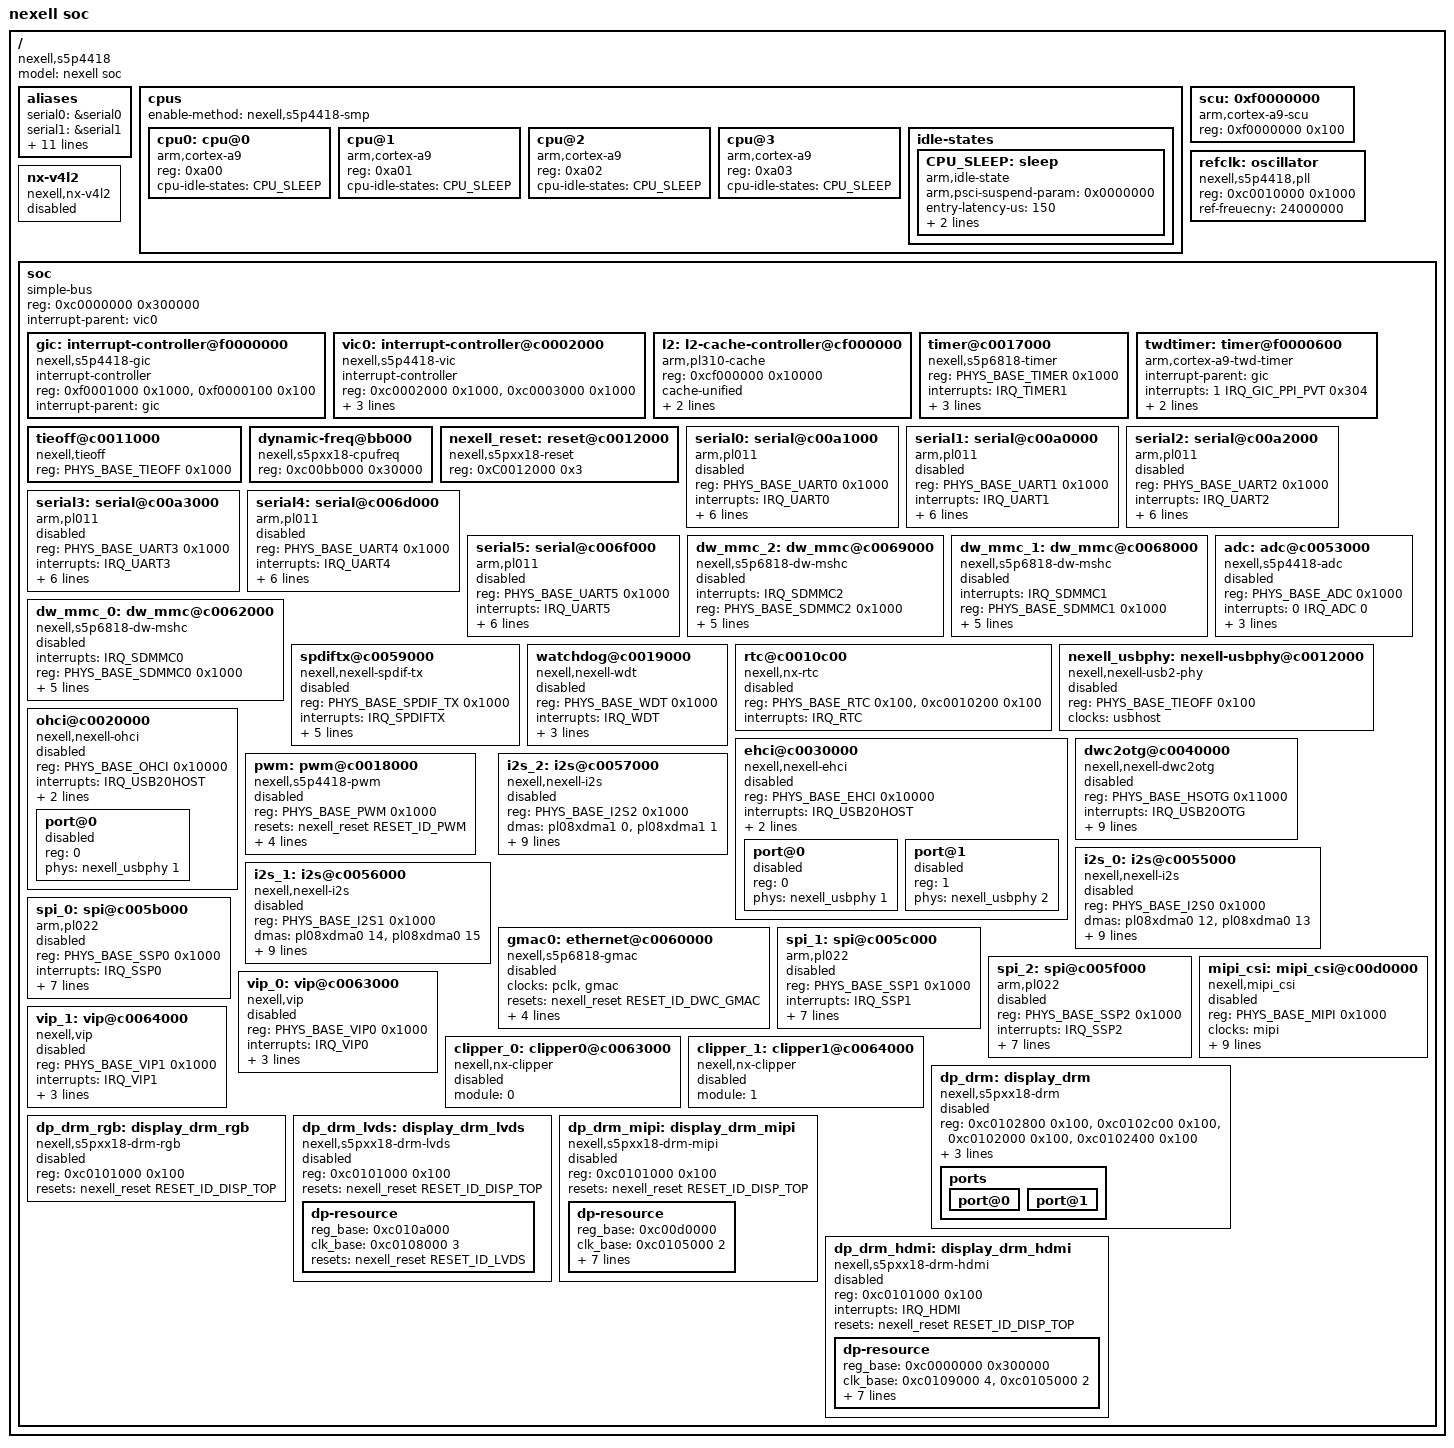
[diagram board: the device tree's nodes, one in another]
/*
 * Copyright (C) 2016  Nexell Co., Ltd.
 * Author: Youngbok, Park <ybpark@nexell.co.kr>
 *
 * This program is free software; you can redistribute it and/or
 * modify it under the terms of the GNU General Public License
 * as published by the Free Software Foundation; either version 2
 * of the License, or (at your option) any later version.
 *
 * This program is distributed in the hope that it will be useful,
 * but WITHOUT ANY WARRANTY; without even the implied warranty of
 * MERCHANTABILITY or FITNESS FOR A PARTICULAR PURPOSE.  See the
 * GNU General Public License for more details.
 *
 * You should have received a copy of the GNU General Public License
 * along with this program.  If not, see <http://www.gnu.org/licenses/>.
 */

#include "../skeleton.dtsi"

#include <dt-bindings/tieoff/s5p4418-tieoff.h>
#include <dt-bindings/soc/s5p4418-base.h>
#include <dt-bindings/reset/nexell,s5p4418-reset.h>
#include <dt-bindings/interrupt-controller/s5p4418-irq.h>
#include <dt-bindings/media/nexell-vip.h>

/ {
	model = "nexell soc";
	compatible = "nexell,s5p4418";
	#address-cells = <0x1>;
	#size-cells = <0x1>;

	aliases {
		serial0 = &serial0;
		serial1 = &serial1;
		serial2 = &serial2;
		serial3 = &serial3;
		serial4 = &serial4;
		serial5 = &serial5;
		i2s0	= &i2s_0;
		i2s1	= &i2s_1;
		i2s2	= &i2s_2;
		spi0	= &spi_0;
		spi1	= &spi_1;
		spi2	= &spi_2;
		pinctrl0 = &pinctrl_0;
	};

	cpus {
		#address-cells = <0x1>;
		#size-cells = <0x0>;
		enable-method = "nexell,s5p4418-smp";

		cpu0: cpu@0 {
			device_type = "cpu";
			compatible = "arm,cortex-a9";
			#cooling-cells = <2>;
			reg = <0xa00>;
			cpu-idle-states =<&CPU_SLEEP>;

		};

		cpu@1 {
			device_type = "cpu";
			compatible = "arm,cortex-a9";
			reg = <0xa01>;
			cpu-idle-states =<&CPU_SLEEP>;
		};

		cpu@2 {
			device_type = "cpu";
			compatible = "arm,cortex-a9";
			reg = <0xa02>;
			cpu-idle-states =<&CPU_SLEEP>;
		};

		cpu@3 {
			device_type = "cpu";
			compatible = "arm,cortex-a9";
			reg = <0xa03>;
			cpu-idle-states =<&CPU_SLEEP>;
		};

		idle-states {
			CPU_SLEEP: sleep {
				compatible = "arm,idle-state";
				arm,psci-suspend-param = <0x0000000>;
				entry-latency-us = <150>;
				exit-latency-us = <200>;
				min-residency-us = <2000>;
			};
		};

	};

	scu:0xf0000000 {
		compatible = "arm,cortex-a9-scu";
		reg = <0xf0000000 0x100>;
	};

	refclk:oscillator {
		compatible = "nexell,s5p4418,pll";
		reg = <0xc0010000 0x1000>;
		ref-freuecny = <24000000>;
	};

	nx-v4l2 {
		compatible = "nexell,nx-v4l2";
		status = "disabled";
	};

	soc {
		compatible = "simple-bus";
		#address-cells = <1>;
		#size-cells = <1>;
		reg = <0xc0000000 0x300000>;
		interrupt-parent = <&vic0>;
		ranges;

		#include "s5p4418-soc.dtsi"

		gic:interrupt-controller@f0000000 {
			compatible = "nexell,s5p4418-gic";
			interrupt-controller;
			#interrupt-cells = <3>;
			reg	= <0xf0001000 0x1000>, <0xf0000100 0x100>;
			interrupt-parent = <&gic>;
		};

		vic0:interrupt-controller@c0002000 {
			compatible = "nexell,s5p4418-vic";
			interrupt-controller;
			reg = <0xc0002000 0x1000>,<0xc0003000 0x1000>;
			#interrupt-cells = <1>;
			valid-mask = <0xffffffff>;
			valid-wakeup-mask =
				< ((1<<IRQ_INTREQPWR) | (1<<IRQ_ALIVE)) >;
		};

		l2:l2-cache-controller@cf000000 {
			compatible = "arm,pl310-cache";
			reg = <0xcf000000 0x10000>;
			cache-unified;
			cache-level = <2>;
			arm,filter-ranges = <0xC0000000 0xFF00000>;
		};

		timer@c0017000 {
			compatible = "nexell,s5p6818-timer";
			reg = <PHYS_BASE_TIMER 0x1000>;
			interrupts = <IRQ_TIMER1>;
			clksource = <0>;
			clkevent = <1>;
			clocks =  <&timer0>, <&timer1>, <&pclk>;
			clock-names = "timer0", "timer1", "pclk";
		};

		twdtimer:timer@f0000600 {
			interrupt-parent = <&gic>;
			interrupts = <1 IRQ_GIC_PPI_PVT 0x304>;
			compatible = "arm,cortex-a9-twd-timer";
			reg = <0xf0000600 0x20>;
			clocks = <&hclk>;
		};

		tieoff@c0011000 {
			compatible = "nexell,tieoff";
			reg = <PHYS_BASE_TIEOFF 0x1000>;
		};

		dynamic-freq@bb000 {
			compatible = "nexell,s5pxx18-cpufreq";
			reg = <0xc00bb000 0x30000>;
		};

		nexell_reset:reset@c0012000 {
			#reset-cells = <1>;
			compatible = "nexell,s5pxx18-reset";
			reg = <0xC0012000 0x3>;
			status = "okay";
		};

		serial0:serial@c00a1000 {
			compatible = "arm,pl011","arm,primecell",
				   "nexell,pl011";
			reg = <PHYS_BASE_UART0 0x1000>;
			interrupts = <IRQ_UART0>;
			clock-names = "uartclk", "apb_pclk";
			clocks = <&uart0>, <&uart0>;
			resets  = <&nexell_reset RESET_ID_UART0>;
			reset-names = "uart-reset";
			soc,tieoff = <NX_TIEOFF_UART0_USESMC 0>,
					<NX_TIEOFF_UART0_SMCTXENB 0>,
					<NX_TIEOFF_UART0_SMCRXENB 0> ;
			pinctrl-names = "default";
			pinctrl-0 = <&serial0_pin>;
			status = "disabled";
		};

		serial1:serial@c00a0000 {
			compatible = "arm,pl011","arm,primecell",
				   "nexell,pl011";
			reg = <PHYS_BASE_UART1 0x1000>;
			interrupts = <IRQ_UART1>;
			clock-names = "uartclk", "apb_pclk";
			clocks = <&uart1>, <&uart1>;
			resets  = <&nexell_reset RESET_ID_UART1>;
			reset-names = "uart-reset";
			soc,tieoff = <NX_TIEOFF_UART1_USESMC 0>,
					<NX_TIEOFF_UART1_SMCTXENB 0>,
					<NX_TIEOFF_UART1_SMCRXENB 0> ;
			pinctrl-names = "default";
			pinctrl-0 = <&serial1_pin>;
			status = "disabled";
		};

		serial2:serial@c00a2000 {
			compatible = "arm,pl011","arm,primecell",
				   "nexell,pl011";
			reg = <PHYS_BASE_UART2 0x1000>;
			interrupts = <IRQ_UART2>;
			clock-names = "uartclk", "apb_pclk";
			clocks = <&uart2>, <&uart2>;
			resets  = <&nexell_reset RESET_ID_UART2>;
			reset-names = "uart-reset";
			soc,tieoff = <NX_TIEOFF_UART2_USESMC 0>,
					<NX_TIEOFF_UART2_SMCTXENB 0>,
					<NX_TIEOFF_UART2_SMCRXENB 0> ;
			pinctrl-names = "default";
			pinctrl-0 = <&serial2_pin>;
			status = "disabled";
		};

		serial3:serial@c00a3000 {
			compatible = "arm,pl011","arm,primecell",
				   "nexell,pl011";
			reg = <PHYS_BASE_UART3 0x1000>;
			interrupts = <IRQ_UART3>;
			clock-names = "uartclk", "apb_pclk";
			clocks = <&uart3>, <&uart3>;
			resets  = <&nexell_reset RESET_ID_UART3>;
			reset-names = "uart-reset";
			soc,tieoff = <NX_TIEOFF_UART3_USESMC 0>,
					<NX_TIEOFF_UART3_SMCTXENB 0>,
					<NX_TIEOFF_UART3_SMCRXENB 0> ;
			pinctrl-names = "default";
			pinctrl-0 = <&serial3_pin>;
			status = "disabled";
		};

		serial4:serial@c006d000 {
			compatible = "arm,pl011","arm,primecell",
				   "nexell,pl011";
			reg = <PHYS_BASE_UART4 0x1000>;
			interrupts = <IRQ_UART4>;
			clock-names = "uartclk", "apb_pclk";
			clocks = <&uart4>, <&uart4>;
			resets  = <&nexell_reset RESET_ID_UART4>;
			reset-names = "uart-reset";
			soc,tieoff = <NX_TIEOFF_UART4_USESMC 0>,
					<NX_TIEOFF_UART4_SMCTXENB 0>,
					<NX_TIEOFF_UART4_SMCRXENB 0> ;
			pinctrl-names = "default";
			pinctrl-0 = <&serial4_pin>;
			status = "disabled";
		};

		serial5:serial@c006f000 {
			compatible = "arm,pl011","arm,primecell",
				   "nexell,pl011";
			reg = <PHYS_BASE_UART5 0x1000>;
			interrupts = <IRQ_UART5>;
			clock-names = "uartclk", "apb_pclk";
			clocks = <&uart5>, <&uart5>;
			resets  = <&nexell_reset RESET_ID_UART5>;
			reset-names = "uart-reset";
			soc,tieoff = <NX_TIEOFF_UART5_USESMC 0>,
					<NX_TIEOFF_UART5_SMCTXENB 0>,
					<NX_TIEOFF_UART5_SMCRXENB 0> ;
			pinctrl-names = "default";
			pinctrl-0 = <&serial5_pin>;
			status = "disabled";
		};


		dw_mmc_2:dw_mmc@c0069000 {
			compatible = "nexell,s5p6818-dw-mshc";
			interrupts = <IRQ_SDMMC2>;
			#address-cells = <1>;
			#size-cells = <0>;
			reg = <PHYS_BASE_SDMMC2 0x1000>;
			resets  = <&nexell_reset RESET_ID_SDMMC2>;
			reset-names = "dw_mmc-reset";
			clock-names = "biu","ciu";
			clocks = <&sdhc2>, <&sdhc2>;
			pinctrl-names = "default";
			pinctrl-0 = <&sdmmc2_cclk &sdmmc2_cmd &sdmmc2_bus4>;
			fifo-detph = <0x20>;
			status = "disabled";
		};

		dw_mmc_1:dw_mmc@c0068000 {
			compatible = "nexell,s5p6818-dw-mshc";
			interrupts = <IRQ_SDMMC1>;
			#address-cells = <1>;
			#size-cells = <0>;
			reg = <PHYS_BASE_SDMMC1 0x1000>;
			resets  = <&nexell_reset RESET_ID_SDMMC1>;
			reset-names = "dw_mmc-reset";
			clock-names = "biu", "ciu";
			clocks = <&sdhc1>, <&sdhc1>;
			pinctrl-names = "default";
			pinctrl-0 = <&sdmmc1_cclk &sdmmc1_cmd &sdmmc1_bus4>;
			fifo-detph = <0x20>;
			status = "disabled";
		};

		dw_mmc_0:dw_mmc@c0062000 {
			compatible = "nexell,s5p6818-dw-mshc";
			interrupts = <IRQ_SDMMC0>;
			#address-cells = <1>;
			#size-cells = <0>;
			reg = <PHYS_BASE_SDMMC0 0x1000>;
			resets  = <&nexell_reset RESET_ID_SDMMC0>;
			reset-names = "dw_mmc-reset";
			clock-names = "biu", "ciu";
			clocks = <&sdhc0>, <&sdhc0>;
			pinctrl-names = "default";
			pinctrl-0 = <&sdmmc0_cclk &sdmmc0_cmd &sdmmc0_bus4>;
			fifo-detph = <0x20>;
			status = "disabled";
		};

		adc:adc@c0053000 {
			compatible = "nexell,s5p4418-adc";
			reg = <PHYS_BASE_ADC 0x1000>;
			interrupts = <0 IRQ_ADC 0>;
			resets = <&nexell_reset RESET_ID_ADC>;
			reset-names = "adc-reset";
			clocks = <&pclk>;
			clock-names = "adc";
			sample_rate = <200000>;
			#io-channel-cells = <1>;
			status = "disabled";
		};

		spdiftx@c0059000 {
			compatible = "nexell,nexell-spdif-tx";
			reg = <PHYS_BASE_SPDIF_TX 0x1000>;
			interrupts = <IRQ_SPDIFTX>;
			dmas = <&pl08xdma1 6>;
			dma-names = "tx";
			resets = <&nexell_reset RESET_ID_SPDIFTX>;
			reset-names = "spdiftx-reset";
			clocks = <&spdiftx>;
			clock-names = "spdif-tx";
			pcm-bit = <16>;
			sample_rate = <48000>;
			status = "disabled";
		};

		watchdog@c0019000 {
			compatible = "nexell,nexell-wdt";
			reg = <PHYS_BASE_WDT 0x1000>;
			interrupts = <IRQ_WDT>;
			resets = <&nexell_reset RESET_ID_WDT>,
			       <&nexell_reset RESET_ID_WDT_POR>;
			reset-names = "wdt-reset","wdt-por-reset";
			clocks = <&pclk>;
			clock-names = "watchdog";
			status = "disabled";
		};

		rtc@c0010c00 {
			compatible = "nexell,nx-rtc";
			reg = <PHYS_BASE_RTC 0x100>, <0xc0010200 0x100>;
			interrupts = <IRQ_RTC>;
			status = "disabled";
		};

		nexell_usbphy: nexell-usbphy@c0012000 {
			compatible = "nexell,nexell-usb2-phy";
			reg = <PHYS_BASE_TIEOFF 0x100>;
			clocks = <&usbhost>;
			clock-names = "phy";
			#phy-cells = <1>;
			status = "disabled";
		};

		ehci@c0030000 {
			compatible = "nexell,nexell-ehci";
			reg = <PHYS_BASE_EHCI 0x10000>;
			interrupts = <IRQ_USB20HOST>;
			clocks = <&usbhost>;
			clock-names = "usbhost";
			resets = <&nexell_reset RESET_ID_USB20HOST>;
			reset-names = "usbhost-reset";
			status = "disabled";
			#address-cells = <1>;
			#size-cells = <0>;
			port@0 {
				reg = <0>;
				phys = <&nexell_usbphy 1>;
				status = "disabled";
			};
			port@1 {
				reg = <1>;
				phys = <&nexell_usbphy 2>;
				status = "disabled";
			};
		};

		ohci@c0020000 {
			compatible = "nexell,nexell-ohci";
			reg = <PHYS_BASE_OHCI 0x10000>;
			interrupts = <IRQ_USB20HOST>;
			clocks = <&usbhost>;
			clock-names = "usbhost";
			resets = <&nexell_reset RESET_ID_USB20HOST>;
			reset-names = "usbhost-reset";
			status = "disabled";
			#address-cells = <1>;
			#size-cells = <0>;
			port@0 {
				reg = <0>;
				phys = <&nexell_usbphy 1>;
				status = "disabled";
			};
		};

		dwc2otg@c0040000 {
			compatible = "nexell,nexell-dwc2otg";
			reg = <PHYS_BASE_HSOTG 0x11000>;
			interrupts = <IRQ_USB20OTG>;
			clocks = <&otg>;
			clock-names = "otg";
			resets = <&nexell_reset RESET_ID_USB20OTG>;
			reset-names = "usbotg-reset";
			phys = <&nexell_usbphy 0>;
			phy-names = "usb2-phy";
			dr_mode = "otg";
			g-use-dma = <1>;
			g-rx-fifo-size = <1064>;
			g-np-tx-fifo-size = <512>;
			g-tx-fifo-size = <512 512 256 256 256 256 256 256 256
			    256 256 256 256 256 256>;
			status = "disabled";
		};

		pwm:pwm@c0018000 {
			compatible = "nexell,s5p4418-pwm";
			reg = <PHYS_BASE_PWM 0x1000>;
			reset-names = "pwm-reset";
			resets  = <&nexell_reset RESET_ID_PWM>;
			clock-names = "timers", "pwm-tclk0", "pwm-tclk1",
			    "pwm-tclk2", "pwm-tclk3";
			clocks =  <&pclk>, <&pwm0>, <&pwm1>, <&pwm2>, <&pwm3>;
			#pwm-cells = <3>;
			pinctrl-names = "default";
			pinctrl-0 = <&pwm0_pin &pwm1_pin &pwm2_pin &pwm3_pin>;
			samsung,pwm-outputs = <0>, <1>, <2>, <3>;
			status = "disabled";
		};

		i2s_0:i2s@c0055000 {
			compatible = "nexell,nexell-i2s";
			reg = <PHYS_BASE_I2S0 0x1000>;
			dmas = <&pl08xdma0 12>, <&pl08xdma0 13>;
			dma-names = "tx", "rx";
			clocks = <&i2s0>;
			clock-names = "i2s0";
			resets = <&nexell_reset RESET_ID_I2S0>;
			reset-names = "i2s-reset";
			pinctrl-names = "default";
			pinctrl-0 = <&i2s0_bus>;
			master-mode = <1>;
			mclk-in = <0>;
			trans-mode = <0>;
			frame-bit = <32>;
			sample-rate = <48000>;
			pre-supply-mclk = <1>;
			status = "disabled";
		};

		i2s_1:i2s@c0056000 {
			compatible = "nexell,nexell-i2s";
			reg = <PHYS_BASE_I2S1 0x1000>;
			dmas = <&pl08xdma0 14>, <&pl08xdma0 15>;
			dma-names = "tx", "rx";
			clocks = <&i2s1>;
			clock-names = "i2s1";
			resets = <&nexell_reset RESET_ID_I2S1>;
			reset-names = "i2s-reset";
			pinctrl-names = "default";
			pinctrl-0 = <&i2s1_bus>;
			master-mode = <1>;
			mclk-in = <0>;
			trans-mode = <0>;
			frame-bit = <32>;
			sample-rate = <48000>;
			pre-supply-mclk = <1>;
			status = "disabled";
		};

		i2s_2:i2s@c0057000 {
			compatible = "nexell,nexell-i2s";
			reg = <PHYS_BASE_I2S2 0x1000>;
			dmas = <&pl08xdma1 0>, <&pl08xdma1 1>;
			dma-names = "tx", "rx";
			clocks = <&i2s2>;
			clock-names = "i2s2";
			resets = <&nexell_reset RESET_ID_I2S2>;
			reset-names = "i2s-reset";
			pinctrl-names = "default";
			pinctrl-0 = <&i2s2_bus>;
			master-mode = <1>;
			mclk-in = <0>;
			trans-mode = <0>;
			frame-bit = <32>;
			sample-rate = <48000>;
			pre-supply-mclk = <1>;
			status = "disabled";
		};

		gmac0:ethernet@c0060000 {
			compatible = "nexell,s5p6818-gmac";
			clocks = <&pclk>, <&gmac>;
			clock-names = "stmmaceth", "nexell_gmac_tx";
			resets = <&nexell_reset RESET_ID_DWC_GMAC>;
			reset-names = "stmmaceth";
			reg = <PHYS_BASE_GMAC 0x2000>;
			interrupts = <IRQ_GMAC>;
			interrupt-names = "macirq";
			mac-address = [000000000000]; /* Filled in by U-Boot */
			phy-mode = "rgmii";
			status = "disable";
		};

		spi_0:spi@c005b000 {
			compatible = "arm,pl022","arm,primecell","nexell,pl022";
			reg = <PHYS_BASE_SSP0 0x1000>;
			interrupts = <IRQ_SSP0>;
			dmas = <&pl08xdma0 6>, <&pl08xdma0 7>;
			arm,primecell-periphid = <0x00041022>;
			dma-names = "tx", "rx";
			resets = <&nexell_reset RESET_ID_SSP0_P>,
			       <&nexell_reset RESET_ID_SSP0>;
			reset-names = "pre-reset","spi-reset";
			#address-cells = <1>;
			#size-cells = <0>;
			num-cs = <1>;
			clocks = <&spi0>, <&spi0>;
			clock-names = "SSPCLK", "apb_pclk";
			pinctrl-names = "default";
			pinctrl-0 = <&spi0_bus>;
			status = "disabled";
		};

		spi_1:spi@c005c000 {
			compatible = "arm,pl022","arm,primecell","nexell,pl022";
			reg = <PHYS_BASE_SSP1 0x1000>;
			interrupts = <IRQ_SSP1>;
			dmas = <&pl08xdma0 8>, <&pl08xdma0 9>;
			arm,primecell-periphid = <0x00041022>;
			dma-names = "tx", "rx";
			resets = <&nexell_reset RESET_ID_SSP1_P>,
			       <&nexell_reset RESET_ID_SSP1>;
			reset-names = "pre-reset","spi-reset";
			#address-cells = <1>;
			#size-cells = <0>;
			num-cs = <1>;
			clocks = <&spi1>, <&spi1>;
			clock-names = "SSPCLK", "apb_pclk";
			pinctrl-names = "default";
			pinctrl-0 = <&spi1_bus>;
			status = "disabled";
		};

		spi_2:spi@c005f000 {
			compatible = "arm,pl022","arm,primecell","nexell,pl022";
			reg = <PHYS_BASE_SSP2 0x1000>;
			interrupts = <IRQ_SSP2>;
			dmas = <&pl08xdma0 10>, <&pl08xdma0 11>;
			arm,primecell-periphid = <0x00041022>;
			dma-names = "tx", "rx";
			resets = <&nexell_reset RESET_ID_SSP2_P>,
			       <&nexell_reset RESET_ID_SSP2>;
			reset-names = "pre-reset","spi-reset";
			#address-cells = <1>;
			#size-cells = <0>;
			num-cs = <1>;
			clocks = <&spi2>, <&spi2>;
			clock-names = "SSPCLK", "apb_pclk";
			pinctrl-names = "default";
			pinctrl-0 = <&spi2_bus>;
			status = "disabled";
		};

		mipi_csi:mipi_csi@c00d0000 {
			compatible = "nexell,mipi_csi";
			reg = <PHYS_BASE_MIPI 0x1000>;
			clock-names = "mipi";
			clocks = <&mipi>;
			reset-names = "mipi-reset", "mipi_csi-reset", "mipi_phy_s-reset";
			resets = <&nexell_reset RESET_ID_MIPI>,
				<&nexell_reset RESET_ID_MIPI_CSI>,
				<&nexell_reset RESET_ID_MIPI_PHY_S>;
			soc,tieoff = <NX_TIEOFF_MIPI0_NX_DPSRAM_1R1W_EMAA 3>;
			data_lane = <2>;
			swap_clocklane = <0>;
			swap_datalane = <0>;
			pllval = <750>;
			status = "disabled";
		};

		vip_0:vip@c0063000 {
			compatible = "nexell,vip";
			reg = <PHYS_BASE_VIP0 0x1000>;
			interrupts = <IRQ_VIP0>;
			clock-names = "vip0";
			clocks = <&vip0>;
			reset-names = "vip0-reset";
			resets = <&nexell_reset RESET_ID_VIP0>;
			module = <0>;
			status = "disabled";
		};

		vip_1:vip@c0064000 {
			compatible = "nexell,vip";
			reg = <PHYS_BASE_VIP1 0x1000>;
			interrupts = <IRQ_VIP1>;
			clock-names = "vip1";
			clocks = <&vip1>;
			reset-names = "vip1-reset";
			resets = <&nexell_reset RESET_ID_VIP1>;
			module = <1>;
			status = "disabled";
		};

		clipper_0:clipper0@c0063000 {
			compatible = "nexell,nx-clipper";
			module = <0>;
			status = "disabled";
		};

		clipper_1:clipper1@c0064000 {
			compatible = "nexell,nx-clipper";
			module = <1>;
			status = "disabled";
		};

		dp_drm: display_drm {
			compatible = "nexell,s5pxx18-drm";
			reg = <0xc0102800 0x100>, <0xc0102c00 0x100>,
				<0xc0102000 0x100>, <0xc0102400 0x100>;
			reg-names = "dpc.0", "dpc.1", "mlc.0", "mlc.1";

			interrupts = <IRQ_DPC_P>, <IRQ_DPC_S>;
			interrupts-names = "dpc.0", "dpc.1";

			resets = <&nexell_reset RESET_ID_DISPLAY>;
			reset-names = "rsc-display";

			status = "disabled";

			ports {
				#address-cells = <1>;
				#size-cells = <0>;
				port@0 { };
				port@1 { };
			};
		};

		dp_drm_rgb: display_drm_rgb {
			compatible = "nexell,s5pxx18-drm-rgb";
			reg = <0xc0101000 0x100>;
			resets = <&nexell_reset RESET_ID_DISP_TOP>;
			reset-names = "rsc-display-top";
			#address-cells = <1>;
			#size-cells = <0>;
			status = "disabled";
		};

		dp_drm_lvds: display_drm_lvds {
			compatible = "nexell,s5pxx18-drm-lvds";
			reg = <0xc0101000 0x100>;
			resets = <&nexell_reset RESET_ID_DISP_TOP>;
			reset-names = "rsc-display-top";
			#address-cells = <1>;
			#size-cells = <0>;
			status = "disabled";

			dp-resource {
				reg_base = <0xc010a000>;
				clk_base = <0xc0108000 3>;
				resets = <&nexell_reset RESET_ID_LVDS>;
				reset-names = "rsc-lvds-phy";
			};
		};

		dp_drm_mipi: display_drm_mipi {
			compatible = "nexell,s5pxx18-drm-mipi";
			reg = <0xc0101000 0x100>;
			resets = <&nexell_reset RESET_ID_DISP_TOP>;
			reset-names = "rsc-display-top";
			#address-cells = <1>;
			#size-cells = <0>;
			status = "disabled";

			dp-resource {
				reg_base = <0xc00d0000>;
				clk_base = <0xc0105000 2>;

				resets = <&nexell_reset RESET_ID_MIPI>,
					<&nexell_reset RESET_ID_MIPI_DSI>,
					<&nexell_reset RESET_ID_MIPI_PHY_S>,
					<&nexell_reset RESET_ID_MIPI_PHY_M>;
				reset-names = "rsc-mipi", "rsc-mipi-dsi",
					"rsc-mipi-phy-s", "rsc-mipi-phy-m";
				soc,tieoff = <NX_TIEOFF_MIPI0_NX_DPSRAM_1R1W_EMAA 3>,
					<NX_TIEOFF_MIPI0_NX_DPSRAM_1R1W_EMAB 3>;
			};
		};

		dp_drm_hdmi: display_drm_hdmi{
			compatible = "nexell,s5pxx18-drm-hdmi";
			reg = <0xc0101000 0x100>;
			interrupts = <IRQ_HDMI>;
			resets = <&nexell_reset RESET_ID_DISP_TOP>;
			reset-names = "rsc-display-top";
			#address-cells = <1>;
			#size-cells = <0>;
			status = "disabled";

			dp-resource {
				reg_base = <0xc0000000 0x300000>;
				clk_base = <0xc0109000 4>, <0xc0105000 2>;
				resets = <&nexell_reset RESET_ID_HDMI_VIDEO>,
						<&nexell_reset RESET_ID_HDMI_SPDIF>,
						<&nexell_reset RESET_ID_HDMI_TMDS>,
						<&nexell_reset RESET_ID_HDMI>,
						<&nexell_reset RESET_ID_HDMI_PHY>;
				reset-names = "rsc-hdmi-video", "rsc-hdmi-spdif",
						"rsc-hdmi-tmds", "rsc-hdmi", "rsc-hdmi-phy";
				soc,tieoff = <NX_TIEOFF_DISPLAYTOP0_i_HDMI_PHY_REFCLK_SEL 1>;
			};
		};
	}; /*** soc ***/
};
